# STM32WB55_CM0P register map
File version: 1.7
CPU: CM0 r0p1, little endian, MPU, no FPU, 4 interrupt priority bits
Registers are 32-bit, read-write, reset 0x0 unless marked. A register's access mark holds for its fields unless they carry their own. Offsets are from the block's base; [hi:lo] are bit positions.

## LPTIM1 — Low power timer
Base 0x40007C00
Same registers: LPTIM2 0x40009400
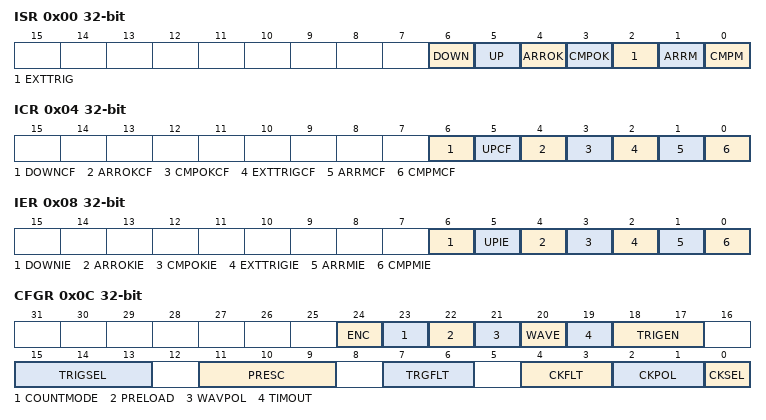
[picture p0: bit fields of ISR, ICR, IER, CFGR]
0x00 ISR ro — Interrupt and Status Register
  [6] DOWN — Counter direction change up to down
  [5] UP — Counter direction change down to up
  [4] ARROK — Autoreload register update OK
  [3] CMPOK — Compare register update OK
  [2] EXTTRIG — External trigger edge event
  [1] ARRM — Autoreload match
  [0] CMPM — Compare match
0x04 ICR wo — Interrupt Clear Register
  [6] DOWNCF — Direction change to down Clear Flag
  [5] UPCF — Direction change to UP Clear Flag
  [4] ARROKCF — Autoreload register update OK Clear Flag
  [3] CMPOKCF — Compare register update OK Clear Flag
  [2] EXTTRIGCF — External trigger valid edge Clear Flag
  [1] ARRMCF — Autoreload match Clear Flag
  [0] CMPMCF — compare match Clear Flag
0x08 IER — Interrupt Enable Register
  [6] DOWNIE — Direction change to down Interrupt Enable
  [5] UPIE — Direction change to UP Interrupt Enable
  [4] ARROKIE — Autoreload register update OK Interrupt Enable
  [3] CMPOKIE — Compare register update OK Interrupt Enable
  [2] EXTTRIGIE — External trigger valid edge Interrupt Enable
  [1] ARRMIE — Autoreload match Interrupt Enable
  [0] CMPMIE — Compare match Interrupt Enable
0x0C CFGR — Configuration Register
  [24] ENC — Encoder mode enable
  [23] COUNTMODE — counter mode enabled
  [22] PRELOAD — Registers update mode
  [21] WAVPOL — Waveform shape polarity
  [20] WAVE — Waveform shape
  [19] TIMOUT — Timeout enable
  [18:17] TRIGEN — Trigger enable and polarity
  [15:13] TRIGSEL — Trigger selector
  [11:9] PRESC — Clock prescaler
  [7:6] TRGFLT — Configurable digital filter for trigger
  [4:3] CKFLT — Configurable digital filter for external clock
  [2:1] CKPOL — Clock Polarity
  [0] CKSEL — Clock selector
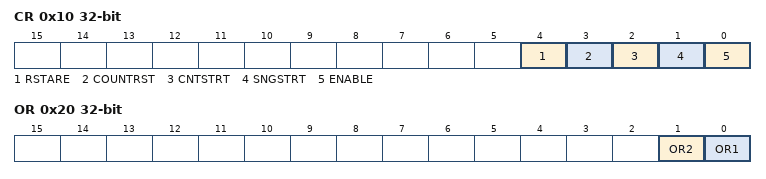
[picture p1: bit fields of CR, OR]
0x10 CR — Control Register
  [4] RSTARE — Reset after read enable
  [3] COUNTRST — Counter reset
  [2] CNTSTRT — Timer start in continuous mode
  [1] SNGSTRT — LPTIM start in single mode
  [0] ENABLE — LPTIM Enable
0x14 CMP — Compare Register
  [15:0] CMP — Compare value
0x18 ARR reset 0x1 — Autoreload Register
  [15:0] ARR — Auto reload value
0x1C CNT ro — Counter Register
  [15:0] CNT — Counter value
0x20 OR — Option Register
  [1] OR2 — Option register bit 2
  [0] OR1 — Option register bit 1

## SPI1 — Serial peripheral interface/Inter-IC sound
Base 0x40013000
Same registers: SPI2 0x40003800
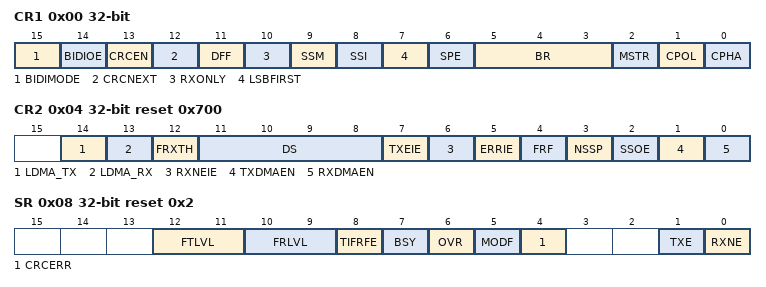
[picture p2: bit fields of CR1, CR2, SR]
0x00 CR1 — control register 1
  [15] BIDIMODE — Bidirectional data mode enable
  [14] BIDIOE — Output enable in bidirectional mode
  [13] CRCEN — Hardware CRC calculation enable
  [12] CRCNEXT — CRC transfer next
  [11] DFF — Data frame format
  [10] RXONLY — Receive only
  [9] SSM — Software slave management
  [8] SSI — Internal slave select
  [7] LSBFIRST — Frame format
  [6] SPE — SPI enable
  [5:3] BR — Baud rate control
  [2] MSTR — Master selection
  [1] CPOL — Clock polarity
  [0] CPHA — Clock phase
0x04 CR2 reset 0x700 — control register 2
  [14] LDMA_TX — Last DMA transfer for transmission
  [13] LDMA_RX — Last DMA transfer for reception
  [12] FRXTH — FIFO reception threshold
  [11:8] DS — Data size
  [7] TXEIE — Tx buffer empty interrupt enable
  [6] RXNEIE — RX buffer not empty interrupt enable
  [5] ERRIE — Error interrupt enable
  [4] FRF — Frame format
  [3] NSSP — NSS pulse management
  [2] SSOE — SS output enable
  [1] TXDMAEN — Tx buffer DMA enable
  [0] RXDMAEN — Rx buffer DMA enable
0x08 SR access per field reset 0x2 — status register
  [12:11] FTLVL ro — FIFO transmission level
  [10:9] FRLVL ro — FIFO reception level
  [8] TIFRFE ro — TI frame format error
  [7] BSY ro — Busy flag
  [6] OVR ro — Overrun flag
  [5] MODF ro — Mode fault
  [4] CRCERR rw — CRC error flag
  [1] TXE ro — Transmit buffer empty
  [0] RXNE ro — Receive buffer not empty
0x0C DR — data register
  [15:0] DR — Data register
0x10 CRCPR reset 0x7 — CRC polynomial register
  [15:0] CRCPOLY
0x14 RXCRCR ro — RX CRC register
  [15:0] RxCRC
0x18 TXCRCR ro — TX CRC register
  [15:0] TxCRC
